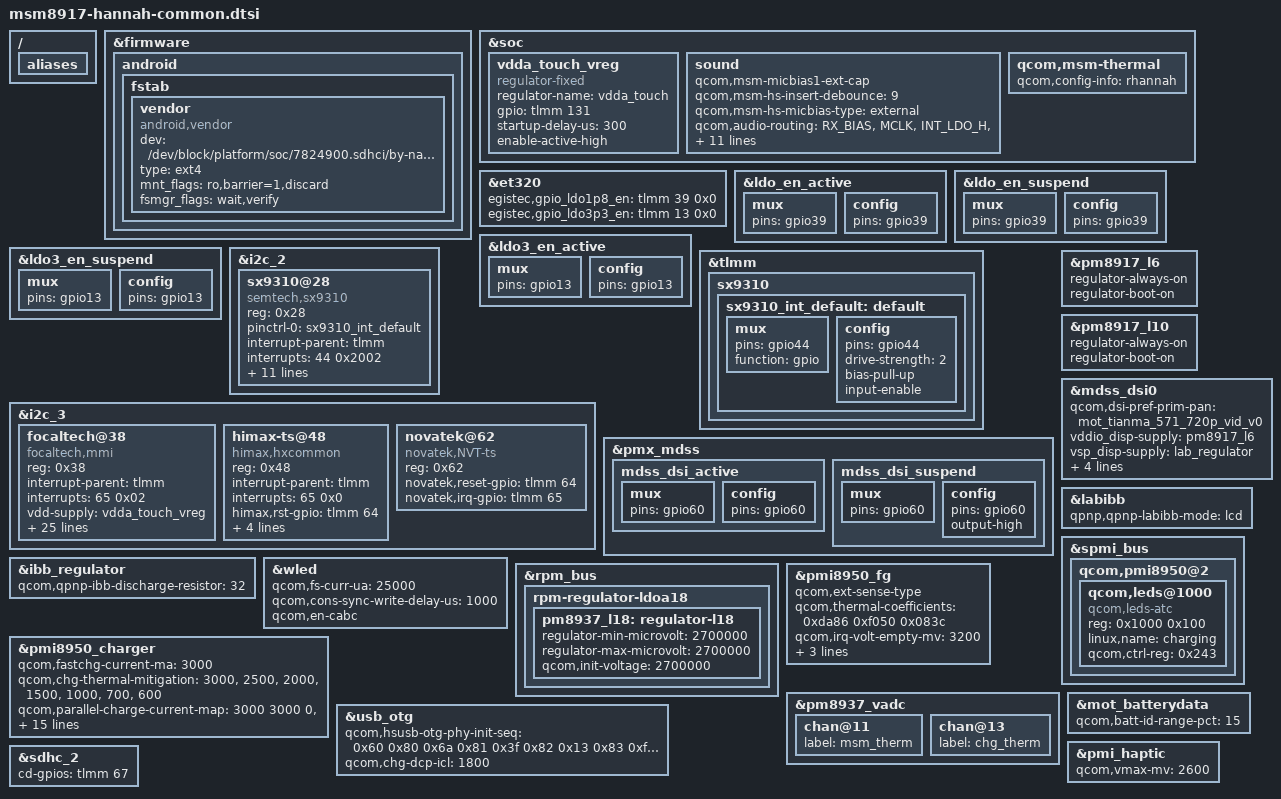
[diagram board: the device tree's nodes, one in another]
/* Copyright (c) 2016, Motorola Mobility Inc. All rights reserved.
 *
 * This program is free software; you can redistribute it and/or modify
 * it under the terms of the GNU General Public License version 2 and
 * only version 2 as published by the Free Software Foundation.
 *
 * This program is distributed in the hope that it will be useful,
 * but WITHOUT ANY WARRANTY; without even the implied warranty of
 * MERCHANTABILITY or FITNESS FOR A PARTICULAR PURPOSE.  See the
 * GNU General Public License for more details.
 */
#include "dsi-panel-mot-tianma-571-720p-video.dtsi"
#include "dsi-panel-mot-djn-599-hd-video.dtsi"
#include "dsi-panel-mot-tianma-599-hd-video.dtsi"
#include "dsi-panel-mot-djn-600-hd-video.dtsi"
#include "dsi-panel-mot-ofilm-599-hd-video.dtsi"
#include "msm8917-moto-common-fps.dtsi"

/ {
	aliases {
		/delete-property/ i2c4;
	};
};

&firmware {
	android {
		fstab {
			vendor {
				compatible = "android,vendor";
				dev = "/dev/block/platform/soc/7824900.sdhci/by-name/vendor";
				type = "ext4";
				mnt_flags = "ro,barrier=1,discard";
				fsmgr_flags = "wait,verify";
				status = "ok";
			};
		};
	};
};



&soc {
	/delete-node/ i2c@78b8000;

	vdda_touch_vreg: vdda_touch_vreg {
		compatible = "regulator-fixed";
		regulator-name = "vdda_touch";
		gpio = <&tlmm 131 0>;
		startup-delay-us = <300>;
		enable-active-high;
	};

	sound {
		/delete-property/ qcom,cdc-us-euro-gpios;
		qcom,msm-micbias1-ext-cap;
		/delete-property/ qcom,msm-micbias2-ext-cap;
		qcom,msm-hs-insert-debounce = <9>;
		qcom,msm-hs-micbias-type = "external";
		qcom,audio-routing =
			"RX_BIAS", "MCLK",
			"INT_LDO_H", "MCLK",
			"MIC BIAS External", "Handset Mic",
			"MIC BIAS External2", "Headset Mic",
			"MIC BIAS External", "Secondary Mic",
			"AMIC1", "MIC BIAS External",
			"AMIC2", "MIC BIAS External2",
			"AMIC3", "MIC BIAS External";
		qcom,msm-gpios =
			"pri_i2s";
		qcom,pinctrl-names =
			"all_off",
			"pri_i2s_act";
		pinctrl-names =
			"all_off",
			"pri_i2s_act";
		pinctrl-0 = <&cdc_pdm_lines_sus &cdc_pdm_lines_2_sus>;
		pinctrl-1 = <&cdc_pdm_lines_act &cdc_pdm_lines_2_act>;
		/delete-property/ pinctrl-2;
		/delete-property/ pinctrl-3;
		/delete-property/ pinctrl-4;
		/delete-property/ pinctrl-5;
		/delete-property/ pinctrl-6;
		/delete-property/ pinctrl-7;
	};

	/delete-node/ fp_id;
};

&et320 {
	egistec,gpio_ldo1p8_en = <&tlmm 39 0x0>;
	egistec,gpio_ldo3p3_en = <&tlmm 13 0x0>;
};

&ldo_en_active {
	mux {
		pins = "gpio39";
	};
	config {
		pins = "gpio39";
	};
};

&ldo_en_suspend {
	mux {
		pins = "gpio39";
	};
	config {
		pins = "gpio39";
	};
};

&ldo3_en_active {
	mux {
		pins = "gpio13";
	};
	config {
		pins = "gpio13";
	};
};

&ldo3_en_suspend {
	mux {
		pins = "gpio13";
	};
	config {
		pins = "gpio13";
	};
};

&tlmm{
	/delete-node/ sx9310;
	sx9310:sx9310 {
		sx9310_int_default: default {
			mux {
				pins = "gpio44";
				function = "gpio";
			};

			config {
				pins = "gpio44";
				drive-strength = <2>;
				bias-pull-up;
				input-enable;
			};
		};
	};
};

&i2c_2 {
	sx9310@28 {
		compatible = "semtech,sx9310";
		reg = <0x28>;
		pinctrl-names = "default";
		pinctrl-0 = <&sx9310_int_default>;
		interrupt-parent = <&tlmm>;
		interrupts = <44 0x2002>;
		cap_vdd-supply = <&pm8917_l10>;
		cap_svdd-supply = <&pm8917_l5>;
		gpios = <&tlmm 44 0x2008>; /* IRQ */
		cap,use_channel = <0x0f>;
		cap,use_channel_top = <0x00>;
		cap,use_channel_bottom = <0x02>;
		cap,raw_data_channel = <0x01>;
		cap,scan_period = <0x02>;
		reg_array_len = <10>;
		reg_array_val = <0x12 0x03 0x13 0x0a 0x14 0x27 0x15 0xc3 0x17 0x4b 0x18 0x49 0x19 0x39 0x21 0x1a 0x22 0x05 0x23 0x20>;
	};

	/delete-node/ adv7533@39;
	/delete-node/ pericom-type-c@1d;
};


&i2c_3 {
	status = "ok";
	/* clock-frequency = <400000>; */
	focaltech@38{
		compatible = "focaltech,mmi";
		reg = <0x38>;
		interrupt-parent = <&tlmm>;
		interrupts = <65 0x02>;
		/* vdd-supply = <&pm8917_l17>; */
		vdd-supply = <&vdda_touch_vreg>;
		vcc_i2c-supply = <&pm8917_l6>;
		/* pins used by touchscreen */
		pinctrl-names = "pmx_ts_active","pmx_ts_suspend","pmx_ts_release";
		pinctrl-0 = <&ts_int_active &ts_reset_active>;
		pinctrl-1 = <&ts_int_suspend &ts_reset_suspend>;
		pinctrl-2 = <&ts_release>;
		focaltech,name = "ft8006u";
		focaltech,family-id = <0xf0>;
		focaltech,reset-gpio = <&tlmm 64 0x01>;
		focaltech,irq-gpio = <&tlmm 65 0x02>;
		focaltech,display-coords = <0 0 720 1440>;
		focaltech,max-touch-number = <10>;
		focaltech,no-force-update;
		focaltech,i2c-pull-up;
		focaltech,group-id = <1>;
		focaltech,hard-reset-delay-ms = <20>;
		focaltech,soft-reset-delay-ms = <200>;
		focaltech,num-max-touches = <10>;
		focaltech,fw-delay-aa-ms = <30>;
		focaltech,fw-delay-55-ms = <30>;
		focaltech,fw-upgrade-id1 = <0x79>;
		focaltech,fw-upgrade-id2 = <0x08>;
		focaltech,fw-delay-readid-ms = <10>;
		focaltech,fw-delay-era-flsh-ms = <2000>;
		focaltech,fw-auto-cal;
		focaltech,resume-in-workqueue;
		focaltech,ignore-id-check;
	};
	himax-ts@48 {
		compatible = "himax,hxcommon";
		reg = <0x48>;
		status = "ok";
		interrupt-parent = <&tlmm>;
		interrupts = <65 0x0>;
		//vcc_i2c-supply = <&pm8917_l6>;
		/* pins used by touchscreen */
		himax,rst-gpio = <&tlmm 64 0x00>;
		himax,irq-gpio = <&tlmm 65 0x00>;
		himax,display-coords = <0 720 0 1440>;
		himax,panel-coords = <0 720 0 1440>;
		//himax,button-map = <158 102 139>;
		//himax,fw-auto-update;
		/*himax,force-update;*/
		report_type = <1>;
	};
	novatek@62 {
		compatible = "novatek,NVT-ts";
		reg = <0x62>;
		status = "ok";

		novatek,reset-gpio = <&tlmm 64 0x00>;
		novatek,irq-gpio = <&tlmm 65 0x00>;
	};

};

&pmx_mdss {
	mdss_dsi_active {
		mux {
			pins = "gpio60";
		};

		config {
			pins = "gpio60";
		};
	};

	mdss_dsi_suspend {
		mux {
			pins = "gpio60";
		};

		config {
			pins = "gpio60";
			output-high;
		};
	};
};

&pm8917_l6 {
	regulator-always-on;
	regulator-boot-on;
};

&pm8917_l10 {
	regulator-always-on;
	regulator-boot-on;
};

&mdss_dsi0 {
	qcom,dsi-pref-prim-pan = <&mot_tianma_571_720p_vid_v0>;
	vddio_disp-supply = <&pm8917_l6>;
	vsp_disp-supply = <&lab_regulator>;
	vsn_disp-supply = <&ibb_regulator>;

	pinctrl-names = "mdss_default", "mdss_sleep";
	pinctrl-0 = <&mdss_dsi_active>;
	pinctrl-1 = <&mdss_dsi_suspend>;

	qcom,platform-reset-gpio = <&tlmm 60 0>;
};

/* display boost and inverting boost regulators */
&labibb {
	status = "ok";
	qpnp,qpnp-labibb-mode = "lcd";
};

&ibb_regulator {
	qcom,qpnp-ibb-discharge-resistor = <32>;
};

&wled {
	qcom,fs-curr-ua = <25000>;
	qcom,cons-sync-write-delay-us = <1000>;
	qcom,en-cabc;
};

&spmi_bus {
	qcom,pmi8950@2 {
		/delete-node/ qcom,leds@a100;
		qcom,leds@1000 {
			status = "ok";
			reg = <0x1000 0x100>;
			compatible = "qcom,leds-atc";
			linux,name = "charging";
			qcom,ctrl-reg = <0x243>;
		};
	};
};

&rpm_bus {
	rpm-regulator-ldoa18 {
		status = "okay";
		pm8937_l18: regulator-l18 {
			regulator-min-microvolt = <2700000>;
			regulator-max-microvolt = <2700000>;
			qcom,init-voltage = <2700000>;
			status = "okay";
		};
	};
};

&pmi8950_charger {
	qcom,fastchg-current-ma = <3000>;
	qcom,chg-thermal-mitigation = <3000>, <2500>,<2000>, <1500>, <1000>,
					<700>, <600>;
	/delete-property/ qcom,dc-thermal-mitigation;
	qcom,parallel-charge-current-map = <3000 3000 0>,
					<2500 2500 0>,
					<2000 2000 0>,
					<1500 1500 0>,
					<1000 1000 0>,
					<700 700 0>,
					<600 600 0>;
	qcom,stepchg-voltage-mv = <4200>;
	qcom,stepchg-current-ma = <2000>;
	qcom,stepchg-taper-ma = <1800>;
	qcom,stepchg-iterm-ma = <125>;
	qcom,enable-hvdcp-9v;
	qcom,weak-charger-check-enable;
	qcom,temp-warm-current-ma = <1500>;
	qcom,temp-cool-current-ma = <900>;
	qcom,temp-slightly-cool-current-ma = <900>;
	qcom,slightly-cool-temp-c = <15>;
	qcom,enable-charging-limit;
	qcom,upper-limit-capacity = <75>;
	qcom,lower-limit-capacity = <60>;
};

&pmi8950_fg {
	qcom,ext-sense-type; /* External Sense Resistor */
	qcom,thermal-coefficients = /bits/ 16 <0xda86 0xf050 0x083c>;
	qcom,irq-volt-empty-mv = <3200>;
	qcom,fg-cutoff-voltage-mv = <3400>;
	qcom,cl-vbat-est-thr-uv = <300000>;
	qcom,fg-force-restart-enable;
	/delete-property/ qcom,support_multi_coefficients;
};

&pm8937_vadc {
	chan@11 {
		label = "msm_therm";
	};

	chan@13 {
		label = "chg_therm";
	};
};

&usb_otg {
	qcom,hsusb-otg-phy-init-seq =
		<0x60 0x80 0x6a 0x81 0x3f 0x82 0x13 0x83 0xffffffff>;
	qcom,chg-dcp-icl = <1800>;
};
&soc{
	qcom,msm-thermal {
		qcom,config-info = "rhannah";
	};
};

&mot_batterydata {
	qcom,batt-id-range-pct = <15>;
	#include "batterydata-he50-atl-pmi8937.dtsi"
	#include "batterydata-he50-cos-pmi8937.dtsi"
	#include "batterydata-he50-cos-pmi8937-r1.dtsi"
};

&pmi_haptic {
	qcom,vmax-mv = <2600>;
	/delete-property/ qcom,en-brake; /* disable internal reverse braking */
	/delete-property/ qcom,brake-pattern; /* disable brake pattern */
};

&sdhc_2 {
	cd-gpios = <&tlmm 67 0x0>;
};

